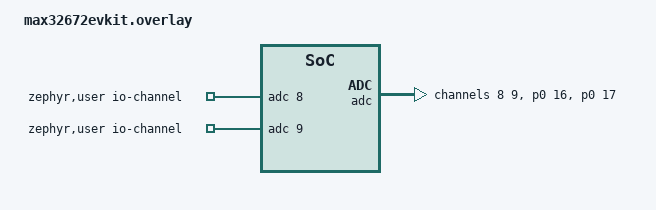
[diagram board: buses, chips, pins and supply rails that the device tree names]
/*
 * Copyright (c) 2024 Analog Devices, Inc.
 *
 * SPDX-License-Identifier: Apache-2.0
 */

/ {
	zephyr,user {
		/* adjust channel number according to pinmux in board.dts */
		io-channels = <&adc 8>, <&adc 9>;
	};
};

&adc {
	status = "okay";
	pinctrl-0 = <&ain8_p0_16 &ain9_p0_17>;
	pinctrl-names = "default";
	#address-cells = <1>;
	#size-cells = <0>;

	channel@8 {
		reg = <8>;
		zephyr,gain = "ADC_GAIN_1";
		zephyr,reference = "ADC_REF_INTERNAL";
		zephyr,acquisition-time = <ADC_ACQ_TIME_DEFAULT>;
		zephyr,resolution = <12>;
	};

	channel@9 {
		reg = <9>;
		zephyr,gain = "ADC_GAIN_1";
		zephyr,reference = "ADC_REF_INTERNAL";
		zephyr,acquisition-time = <ADC_ACQ_TIME_DEFAULT>;
		zephyr,resolution = <12>;
	};
};
